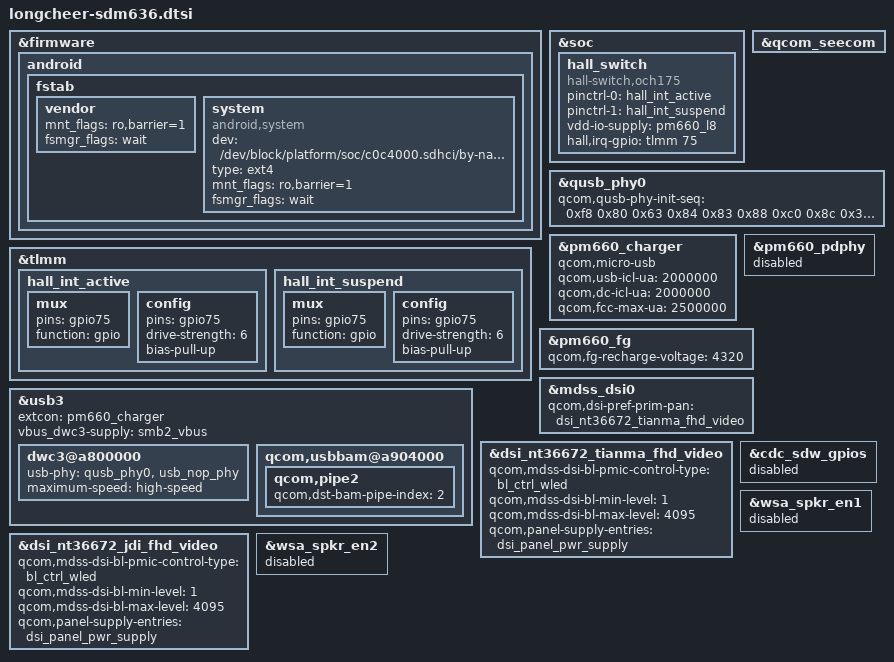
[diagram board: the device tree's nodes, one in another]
// SPDX-License-Identifier: GPL-2.0-only

#include "longcheer-sdm636-audio.dtsi"
#include "longcheer-sdm636-pinctrl.dtsi"
#include "longcheer-sdm660-base.dtsi"

/* sdm660.dtsi tulip/whyred specific diff */
&firmware {
	android {
		/delete-node/ vbmeta;
		fstab {
			vendor {
				mnt_flags = "ro,barrier=1";
				fsmgr_flags = "wait";
			};

			system {
				compatible = "android,system";
				dev = "/dev/block/platform/soc/c0c4000.sdhci/by-name/system";
				type = "ext4";
				mnt_flags = "ro,barrier=1";
				fsmgr_flags = "wait";
				status = "ok";
			};
		};
	};
};

&tlmm {
	hall_int_active:hall_int_active {
		mux {
			pins = "gpio75";
			function = "gpio";
		};

		config {
			pins = "gpio75";
			drive-strength = <6>;
			bias-pull-up;
		};
	};

	hall_int_suspend: hall_int_suspend {
		mux {
			pins = "gpio75";
			function = "gpio";
		};

		config {
			pins = "gpio75";
			drive-strength = <6>;
			bias-pull-up;
		};
	};
};

&soc {
	hall_switch {
		compatible = "hall-switch,och175";
		pinctrl-names = "hall_active","hall_suspend";
		pinctrl-0 = <&hall_int_active>;
		pinctrl-1 = <&hall_int_suspend>;
		vdd-io-supply= <&pm660_l8>;
		interrupt-names = "hall_irq";
		hall,irq-gpio = <&tlmm 75 0x0>;
	};
};

&qcom_seecom {
	/delete-property/ qcom,fde-key-size;
};

/* sdm660-common.dtsi tulip/whyred specific diff */
&usb3 {
	extcon = <&pm660_charger>;
	vbus_dwc3-supply = <&smb2_vbus>;

	dwc3@a800000 {
		usb-phy = <&qusb_phy0>, <&usb_nop_phy>;
		maximum-speed = "high-speed";
	};

	qcom,usbbam@a904000 {
		qcom,pipe2 {
			qcom,dst-bam-pipe-index = <2>;
		};
	};
};

&qusb_phy0 {
	qcom,qusb-phy-init-seq = <
		0xf8 0x80
		0x63 0x84
		0x83 0x88
		0xc0 0x8c
		0x30 0x08
		0x79 0x0c
		0x21 0x10
		0x14 0x9c
		0x9f 0x1c
		0x00 0x18
	>;
};

/* msm-pm660.dtsi tulip/whyred specific diff */
&pm660_charger {
	qcom,micro-usb;
};

&pm660_charger {
	qcom,usb-icl-ua = <2000000>;
	qcom,dc-icl-ua = <2000000>;
	qcom,fcc-max-ua = <2500000>;
};

&pm660_pdphy {
	status = "disabled";
};

&pm660_fg {
	qcom,fg-recharge-voltage = <4320>;
};

/* sdm636-mtp.dtsi diff */
&mdss_dsi0 {
	qcom,dsi-pref-prim-pan = <&dsi_nt36672_tianma_fhd_video>;
};

&dsi_nt36672_tianma_fhd_video {
	qcom,mdss-dsi-bl-pmic-control-type = "bl_ctrl_wled";
	qcom,mdss-dsi-bl-min-level = <1>;
	qcom,mdss-dsi-bl-max-level = <4095>;
	qcom,panel-supply-entries = <&dsi_panel_pwr_supply>;
};

&dsi_nt36672_jdi_fhd_video {
	qcom,mdss-dsi-bl-pmic-control-type = "bl_ctrl_wled";
	qcom,mdss-dsi-bl-min-level = <1>;
	qcom,mdss-dsi-bl-max-level = <4095>;
	qcom,panel-supply-entries = <&dsi_panel_pwr_supply>;
};

/* sdm636-audio-dtsi diff */
&cdc_sdw_gpios {
	status = "disabled";
};

&wsa_spkr_en1 {
	status = "disabled";
};

&wsa_spkr_en2 {
	status = "disabled";
};
